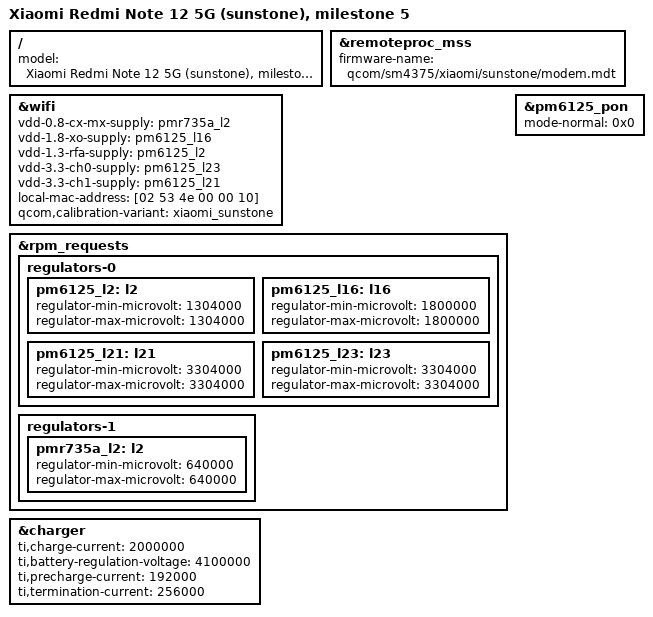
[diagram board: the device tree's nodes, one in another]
// SPDX-License-Identifier: BSD-3-Clause
/*
 * Xiaomi Redmi Note 12 5G (sunstone), SM4375 "blair": milestone 5 tree = M4 + modem and Wi-Fi.
 *
 * The modem (MPSS PAS) runs the WLAN firmware of the WCN3988 (chip 0x150, WLAN.HL.3.3.2); Linux
 * talks to it through ath10k snoc. Firmware comes read-only from the phone's modem_a partition
 * (sunstone-fw-install in rootfs-overlay); rmtfs serves copies of modemst1/2, fsg and fsc, so
 * the EFS partitions are never written. WLAN supplies as on the downstream icnss node (and
 * Sony's pdx225): cx-mx PMR735A L2, 1.8 V XO PM6125 L16, 1.3 V RFA PM6125 L2, 3.3 V ch0/ch1
 * PM6125 L23/L21. MSA at wlan@86500000 and the modem carveout at 0x8b800000 match the dtsi.
 */
#include "sm4375-xiaomi-sunstone-m4.dts"

/ {
	model = "Xiaomi Redmi Note 12 5G (sunstone), milestone 5";
};

&remoteproc_mss {
	firmware-name = "qcom/sm4375/xiaomi/sunstone/modem.mdt";
	status = "okay";
};

&wifi {
	vdd-0.8-cx-mx-supply = <&pmr735a_l2>;
	vdd-1.8-xo-supply = <&pm6125_l16>;
	vdd-1.3-rfa-supply = <&pm6125_l2>;
	vdd-3.3-ch0-supply = <&pm6125_l23>;
	vdd-3.3-ch1-supply = <&pm6125_l21>;
	/*
	 * The firmware reports 00:00:.. and ath10k would pick a random address every boot (new
	 * DHCP lease each time). A fixed locally administered address instead of the phone's own
	 * MAC from persist, which stays out of this repository.
	 */
	local-mac-address = [02 53 4e 00 00 10];
	/*
	 * The board ID in OTP is unset (0xff), which matches only linux-firmware's generic entry. With
	 * the variant, ath10k first looks for "...,qmi-chip-id=150,variant=xiaomi_sunstone" in
	 * board-2.bin: an entry made from the phone's own bdwlan file (sunstone-fw-install, into
	 * /lib/firmware/updates), the generic entry as the fallback.
	 */
	qcom,calibration-variant = "xiaomi_sunstone";
	status = "okay";
};

&rpm_requests {
	regulators-0 {
		pm6125_l2: l2 {
			regulator-min-microvolt = <1304000>;
			regulator-max-microvolt = <1304000>;
		};

		pm6125_l16: l16 {
			regulator-min-microvolt = <1800000>;
			regulator-max-microvolt = <1800000>;
		};

		pm6125_l21: l21 {
			regulator-min-microvolt = <3304000>;
			regulator-max-microvolt = <3304000>;
		};

		pm6125_l23: l23 {
			regulator-min-microvolt = <3304000>;
			regulator-max-microvolt = <3304000>;
		};
	};

	regulators-1 {
		pmr735a_l2: l2 {
			regulator-min-microvolt = <640000>;
			regulator-max-microvolt = <640000>;
		};
	};
};

/*
 * A normal `reboot` writes PON reason 0 and comes back into Linux; `reboot bootloader`
 * (`systemctl reboot --reboot-argument=bootloader`, mode-bootloader in pm6125.dtsi) goes to fastboot.
 * A panic (emergency restart, no reboot notifiers) leaves the reason as it was: since 2026-10-23 the
 * shim no longer sets "bootloader" before Linux (unless built with PON_FASTBOOT=1), so it reboots
 * into Linux too.
 */
&pm6125_pon {
	mode-normal = <0x0>;
};

/*
 * Charging: with linux,read-back-settings the driver caps ICHG at what the bootloader left
 * (512 mA). Program it instead, below the downstream 3 A: 2 A (about 1.86 A on the SC89890H,
 * whose ICHG step is smaller), precharge/termination as read back on boot-13. Input current stays
 * with the chip's own BC1.2 detection; no reset; JEITA via the TS pin in hardware.
 * CV 4.1 V (4.096 V in 16 mV steps, about 80 %) rather than the downstream 4.45 V: the phone lives
 * on its charger as a server and the battery is its UPS; 24/7 at 4.45 V ages it fast. For a full
 * charge: echo 4450000 > /sys/class/power_supply/bq25890-charger-0/constant_charge_voltage
 */
&charger {
	/delete-property/ linux,read-back-settings;
	ti,charge-current = <2000000>;
	ti,battery-regulation-voltage = <4100000>;
	ti,precharge-current = <192000>;
	ti,termination-current = <256000>;
};
